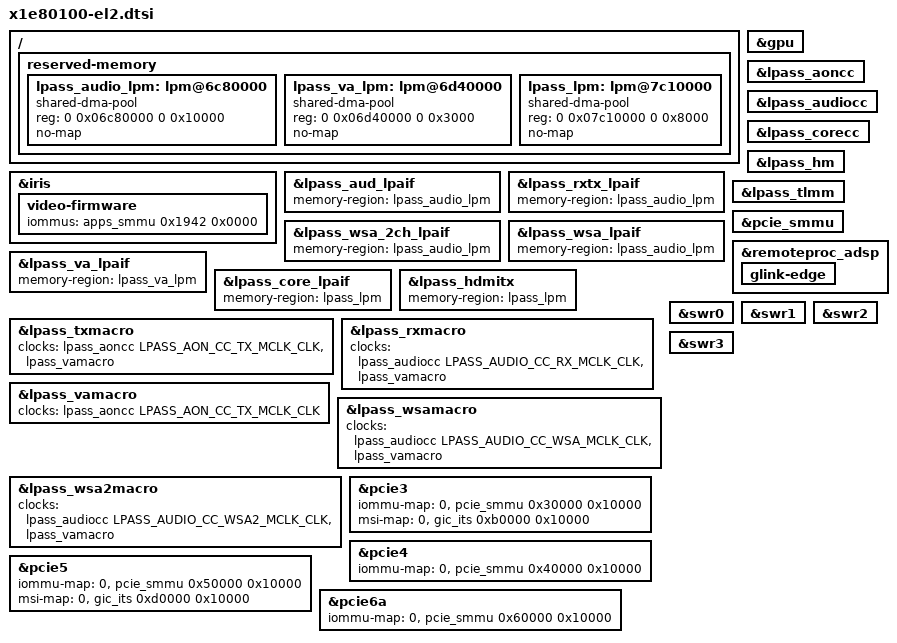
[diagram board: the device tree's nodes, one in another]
// SPDX-License-Identifier: BSD-3-Clause
/*
 * Copyright (c) 2024, Jonathan Marek
 */

#include <dt-bindings/sound/qcom,lpaif-v5.h>

/* NOTE: many of the reserved-memory regions can be deleted,
 * but most of them are excluded by EFI memory and just deleting
 * them from DTB is not enough to make the memory available
 */

/ {
	/delete-node/ smp2p-cdsp;
	/delete-node/ sound;

	reserved-memory {
		/* not regular memory: */

		lpass_audio_lpm: lpm@6c80000 {
			compatible = "shared-dma-pool";
			reg = <0 0x06c80000 0 0x10000>;
			no-map;
		};

		lpass_va_lpm: lpm@6d40000 {
			compatible = "shared-dma-pool";
			reg = <0 0x06d40000 0 0x3000>;
			no-map;
		};

		lpass_lpm: lpm@7c10000 {
			compatible = "shared-dma-pool";
			reg = <0 0x07c10000 0 0x8000>;
			no-map;
		};
	};
};

&gpu {
	/delete-node/ zap-shader;
};

&iris {
	video-firmware {
		iommus = <&apps_smmu 0x1942 0x0000>;
	};
};

/delete-node/ &not_lpass_audiocc;
/delete-node/ &not_lpasscc;
/delete-node/ &sbsa_watchdog;

&lpass_aoncc {
	status = "okay";
};

&lpass_audiocc {
	status = "okay";
};

&lpass_corecc {
	status = "okay";
};

&lpass_hm {
	status = "okay";
};

&lpass_aud_lpaif {
	status = "okay";
	memory-region = <&lpass_audio_lpm>;
};

&lpass_rxtx_lpaif {
	status = "okay";
	memory-region = <&lpass_audio_lpm>;
};

&lpass_wsa_2ch_lpaif {
	status = "okay";
	memory-region = <&lpass_audio_lpm>;
};

&lpass_wsa_lpaif {
	status = "okay";
	memory-region = <&lpass_audio_lpm>;
};

&lpass_va_lpaif {
	status = "okay";
	memory-region = <&lpass_va_lpm>;
};

&lpass_core_lpaif {
	status = "okay";
	memory-region = <&lpass_lpm>;
};

&lpass_hdmitx {
	status = "okay";
	memory-region = <&lpass_lpm>;
};

&lpass_tlmm {
	/delete-property/ clocks;
	/delete-property/ clocks-names;
};

&lpass_txmacro {
	clocks = <&lpass_aoncc LPASS_AON_CC_TX_MCLK_CLK>, <&lpass_vamacro>;
	clock-names = "mclk", "fsgen";
};

&lpass_rxmacro {
	clocks = <&lpass_audiocc LPASS_AUDIO_CC_RX_MCLK_CLK>, <&lpass_vamacro>;
	clock-names = "mclk", "fsgen";
};

&lpass_vamacro {
	clocks = <&lpass_aoncc LPASS_AON_CC_TX_MCLK_CLK>;
	clock-names = "mclk";
};

&lpass_wsamacro {
	clocks = <&lpass_audiocc LPASS_AUDIO_CC_WSA_MCLK_CLK>, <&lpass_vamacro>;
	clock-names = "mclk", "fsgen";
};

&lpass_wsa2macro {
	clocks = <&lpass_audiocc LPASS_AUDIO_CC_WSA2_MCLK_CLK>, <&lpass_vamacro>;
	clock-names = "mclk", "fsgen";
};

&pcie3 {
	iommu-map = <0 &pcie_smmu 0x30000 0x10000>;
	msi-map = <0 &gic_its 0xb0000 0x10000>;
};

&pcie4 {
	iommu-map = <0 &pcie_smmu 0x40000 0x10000>;
};

&pcie5 {
	iommu-map = <0 &pcie_smmu 0x50000 0x10000>;
	msi-map = <0 &gic_its 0xd0000 0x10000>;
};

&pcie6a {
	iommu-map = <0 &pcie_smmu 0x60000 0x10000>;
};

&pcie_smmu {
	status = "okay";
};

&remoteproc_adsp {
	/delete-property/ firmware-name;
	glink-edge {
		/delete-node/ fastrpc;
		/delete-node/ gpr;
	};
};

/delete-node/ &remoteproc_cdsp;

&swr0 {
	/delete-property/ resets;
	/delete-property/ reset-names;
};

&swr1 {
	/delete-property/ resets;
	/delete-property/ reset-names;
};

&swr2 {
	/delete-property/ resets;
	/delete-property/ reset-names;
};

&swr3 {
	/delete-property/ resets;
	/delete-property/ reset-names;
};
